AUTOSAR XML (schema 4-2-1)
package /RootP_ASWC_ParamServer
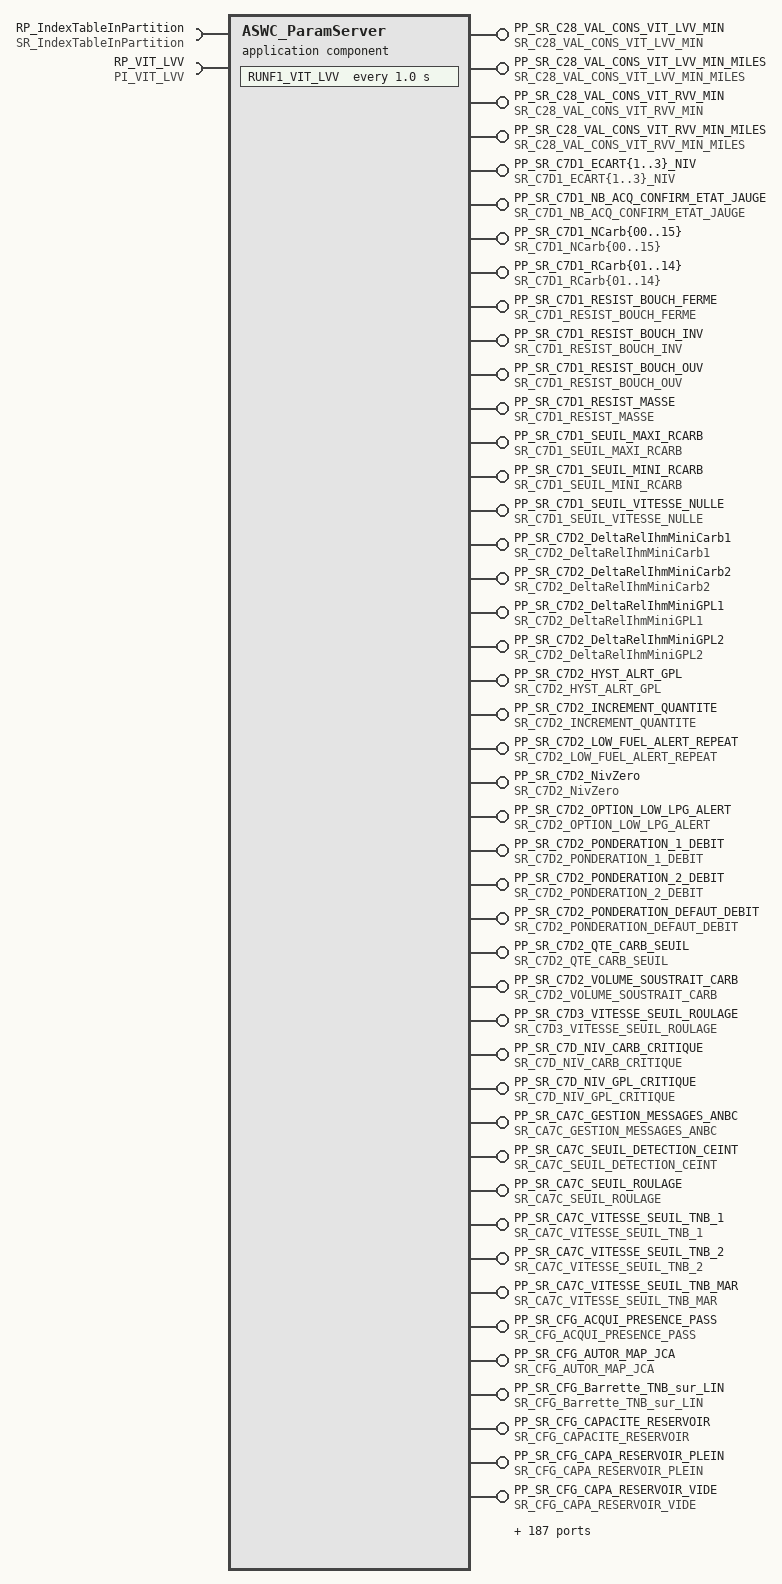
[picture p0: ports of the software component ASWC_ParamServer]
  application sw component type ASWC_ParamServer
    296 x provide port:
      PP_SR_C28_VAL_CONS_VIT_LVV_MIN: provided-interface=SR_C28_VAL_CONS_VIT_LVV_MIN
      PP_SR_C28_VAL_CONS_VIT_LVV_MIN_MILES: provided-interface=SR_C28_VAL_CONS_VIT_LVV_MIN_MILES
      PP_SR_C28_VAL_CONS_VIT_RVV_MIN: provided-interface=SR_C28_VAL_CONS_VIT_RVV_MIN
      PP_SR_C28_VAL_CONS_VIT_RVV_MIN_MILES: provided-interface=SR_C28_VAL_CONS_VIT_RVV_MIN_MILES
      PP_SR_C7D1_ECART{1..3}_NIV: nonqueued-sender-com-spec{data-element=C7D1_ECART{1..3}_NIV, uses-end-to-end-protection=0, init-value=0}, provided-interface=SR_C7D1_ECART{1..3}_NIV
      PP_SR_C7D1_NB_ACQ_CONFIRM_ETAT_JAUGE: nonqueued-sender-com-spec{data-element=C7D1_NB_ACQ_CONFIRM_ETAT_JAUGE, uses-end-to-end-protection=0, init-value=0}, provided-interface=SR_C7D1_NB_ACQ_CONFIRM_ETAT_JAUGE
      PP_SR_C7D1_NCarb{00..15}: nonqueued-sender-com-spec{data-element=C7D1_NCarb{00..15}, uses-end-to-end-protection=0, init-value=0}, provided-interface=SR_C7D1_NCarb{00..15}
      PP_SR_C7D1_RCarb{01..14}: nonqueued-sender-com-spec{data-element=C7D1_RCarb{01..14}, uses-end-to-end-protection=0, init-value=0}, provided-interface=SR_C7D1_RCarb{01..14}
      PP_SR_C7D1_RESIST_BOUCH_FERME: nonqueued-sender-com-spec{data-element=C7D1_RESIST_BOUCH_FERME, uses-end-to-end-protection=0, init-value=0}, provided-interface=SR_C7D1_RESIST_BOUCH_FERME
      PP_SR_C7D1_RESIST_BOUCH_INV: nonqueued-sender-com-spec{data-element=C7D1_RESIST_BOUCH_INV, uses-end-to-end-protection=0, init-value=0}, provided-interface=SR_C7D1_RESIST_BOUCH_INV
      PP_SR_C7D1_RESIST_BOUCH_OUV: nonqueued-sender-com-spec{data-element=C7D1_RESIST_BOUCH_OUV, uses-end-to-end-protection=0, init-value=0}, provided-interface=SR_C7D1_RESIST_BOUCH_OUV
      PP_SR_C7D1_RESIST_MASSE: nonqueued-sender-com-spec{data-element=C7D1_RESIST_MASSE, uses-end-to-end-protection=0, init-value=0}, provided-interface=SR_C7D1_RESIST_MASSE
      PP_SR_C7D1_SEUIL_MAXI_RCARB: nonqueued-sender-com-spec{data-element=C7D1_SEUIL_MAXI_RCARB, uses-end-to-end-protection=0, init-value=0}, provided-interface=SR_C7D1_SEUIL_MAXI_RCARB
      PP_SR_C7D1_SEUIL_MINI_RCARB: nonqueued-sender-com-spec{data-element=C7D1_SEUIL_MINI_RCARB, uses-end-to-end-protection=0, init-value=0}, provided-interface=SR_C7D1_SEUIL_MINI_RCARB
      PP_SR_C7D1_SEUIL_VITESSE_NULLE: nonqueued-sender-com-spec{data-element=C7D1_SEUIL_VITESSE_NULLE, uses-end-to-end-protection=0, init-value=0}, provided-interface=SR_C7D1_SEUIL_VITESSE_NULLE
      PP_SR_C7D2_DeltaRelIhmMiniCarb1: nonqueued-sender-com-spec{data-element=C7D2_DeltaRelIhmMiniCarb1, uses-end-to-end-protection=0, init-value=0}, provided-interface=SR_C7D2_DeltaRelIhmMiniCarb1
      PP_SR_C7D2_DeltaRelIhmMiniCarb2: nonqueued-sender-com-spec{data-element=C7D2_DeltaRelIhmMiniCarb2, uses-end-to-end-protection=0, init-value=0}, provided-interface=SR_C7D2_DeltaRelIhmMiniCarb2
      PP_SR_C7D2_DeltaRelIhmMiniGPL1: nonqueued-sender-com-spec{data-element=C7D2_DeltaRelIhmMiniGPL1, uses-end-to-end-protection=0, init-value=0}, provided-interface=SR_C7D2_DeltaRelIhmMiniGPL1
      PP_SR_C7D2_DeltaRelIhmMiniGPL2: nonqueued-sender-com-spec{data-element=C7D2_DeltaRelIhmMiniGPL2, uses-end-to-end-protection=0, init-value=0}, provided-interface=SR_C7D2_DeltaRelIhmMiniGPL2
      PP_SR_C7D2_HYST_ALRT_GPL: nonqueued-sender-com-spec{data-element=C7D2_HYST_ALRT_GPL, uses-end-to-end-protection=0, init-value=0}, provided-interface=SR_C7D2_HYST_ALRT_GPL
      PP_SR_C7D2_INCREMENT_QUANTITE: nonqueued-sender-com-spec{data-element=C7D2_INCREMENT_QUANTITE, uses-end-to-end-protection=0, init-value=0}, provided-interface=SR_C7D2_INCREMENT_QUANTITE
      PP_SR_C7D2_LOW_FUEL_ALERT_REPEAT: nonqueued-sender-com-spec{data-element=C7D2_LOW_FUEL_ALERT_REPEAT, uses-end-to-end-protection=0, init-value=0}, provided-interface=SR_C7D2_LOW_FUEL_ALERT_REPEAT
      PP_SR_C7D2_NivZero: nonqueued-sender-com-spec{data-element=C7D2_NivZero, uses-end-to-end-protection=0, init-value=0}, provided-interface=SR_C7D2_NivZero
      PP_SR_C7D2_OPTION_LOW_LPG_ALERT: nonqueued-sender-com-spec{data-element=C7D2_OPTION_LOW_LPG_ALERT, uses-end-to-end-protection=0, init-value=0}, provided-interface=SR_C7D2_OPTION_LOW_LPG_ALERT
      PP_SR_C7D2_PONDERATION_1_DEBIT: nonqueued-sender-com-spec{data-element=C7D2_PONDERATION_1_DEBIT, uses-end-to-end-protection=0, init-value=0}, provided-interface=SR_C7D2_PONDERATION_1_DEBIT
      PP_SR_C7D2_PONDERATION_2_DEBIT: nonqueued-sender-com-spec{data-element=C7D2_PONDERATION_2_DEBIT, uses-end-to-end-protection=0, init-value=0}, provided-interface=SR_C7D2_PONDERATION_2_DEBIT
      PP_SR_C7D2_PONDERATION_DEFAUT_DEBIT: nonqueued-sender-com-spec{data-element=C7D2_PONDERATION_DEFAUT_DEBIT, uses-end-to-end-protection=0, init-value=0}, provided-interface=SR_C7D2_PONDERATION_DEFAUT_DEBIT
      PP_SR_C7D2_QTE_CARB_SEUIL: nonqueued-sender-com-spec{data-element=C7D2_QTE_CARB_SEUIL, uses-end-to-end-protection=0, init-value=0}, provided-interface=SR_C7D2_QTE_CARB_SEUIL
      PP_SR_C7D2_VOLUME_SOUSTRAIT_CARB: nonqueued-sender-com-spec{data-element=C7D2_VOLUME_SOUSTRAIT_CARB, uses-end-to-end-protection=0, init-value=0}, provided-interface=SR_C7D2_VOLUME_SOUSTRAIT_CARB
      PP_SR_C7D3_VITESSE_SEUIL_ROULAGE: nonqueued-sender-com-spec{data-element=C7D3_VITESSE_SEUIL_ROULAGE, uses-end-to-end-protection=0, init-value=0}, provided-interface=SR_C7D3_VITESSE_SEUIL_ROULAGE
      PP_SR_C7D_NIV_CARB_CRITIQUE: nonqueued-sender-com-spec{data-element=C7D_NIV_CARB_CRITIQUE, uses-end-to-end-protection=0, init-value=0}, provided-interface=SR_C7D_NIV_CARB_CRITIQUE
      PP_SR_C7D_NIV_GPL_CRITIQUE: nonqueued-sender-com-spec{data-element=C7D_NIV_GPL_CRITIQUE, uses-end-to-end-protection=0, init-value=0}, provided-interface=SR_C7D_NIV_GPL_CRITIQUE
      PP_SR_CA7C_GESTION_MESSAGES_ANBC: nonqueued-sender-com-spec{data-element=CA7C_GESTION_MESSAGES_ANBC, uses-end-to-end-protection=0, init-value=0}, provided-interface=SR_CA7C_GESTION_MESSAGES_ANBC
      PP_SR_CA7C_SEUIL_DETECTION_CEINT: nonqueued-sender-com-spec{data-element=CA7C_SEUIL_DETECTION_CEINT, uses-end-to-end-protection=0, init-value=0}, provided-interface=SR_CA7C_SEUIL_DETECTION_CEINT
      PP_SR_CA7C_SEUIL_ROULAGE: nonqueued-sender-com-spec{data-element=CA7C_SEUIL_ROULAGE, uses-end-to-end-protection=0, init-value=0}, provided-interface=SR_CA7C_SEUIL_ROULAGE
      PP_SR_CA7C_VITESSE_SEUIL_TNB_1: nonqueued-sender-com-spec{data-element=CA7C_VITESSE_SEUIL_TNB_1, uses-end-to-end-protection=0, init-value=0}, provided-interface=SR_CA7C_VITESSE_SEUIL_TNB_1
      PP_SR_CA7C_VITESSE_SEUIL_TNB_2: nonqueued-sender-com-spec{data-element=CA7C_VITESSE_SEUIL_TNB_2, uses-end-to-end-protection=0, init-value=0}, provided-interface=SR_CA7C_VITESSE_SEUIL_TNB_2
      PP_SR_CA7C_VITESSE_SEUIL_TNB_MAR: nonqueued-sender-com-spec{data-element=CA7C_VITESSE_SEUIL_TNB_MAR, uses-end-to-end-protection=0, init-value=0}, provided-interface=SR_CA7C_VITESSE_SEUIL_TNB_MAR
      PP_SR_CFG_ACQUI_PRESENCE_PASS: nonqueued-sender-com-spec{data-element=CFG_ACQUI_PRESENCE_PASS, uses-end-to-end-protection=0, init-value=0}, provided-interface=SR_CFG_ACQUI_PRESENCE_PASS
      PP_SR_CFG_AUTOR_MAP_JCA: nonqueued-sender-com-spec{data-element=CFG_AUTOR_MAP_JCA, uses-end-to-end-protection=0, init-value=0}, provided-interface=SR_CFG_AUTOR_MAP_JCA
      PP_SR_CFG_Barrette_TNB_sur_LIN: nonqueued-sender-com-spec{data-element=CFG_Barrette_TNB_sur_LIN, uses-end-to-end-protection=0, init-value=0}, provided-interface=SR_CFG_Barrette_TNB_sur_LIN
      PP_SR_CFG_CAPACITE_RESERVOIR: nonqueued-sender-com-spec{data-element=CFG_CAPACITE_RESERVOIR, uses-end-to-end-protection=0, init-value=0}, provided-interface=SR_CFG_CAPACITE_RESERVOIR
      PP_SR_CFG_CAPA_RESERVOIR_PLEIN: nonqueued-sender-com-spec{data-element=CFG_CAPA_RESERVOIR_PLEIN, uses-end-to-end-protection=0, init-value=0}, provided-interface=SR_CFG_CAPA_RESERVOIR_PLEIN
      PP_SR_CFG_CAPA_RESERVOIR_VIDE: nonqueued-sender-com-spec{data-element=CFG_CAPA_RESERVOIR_VIDE, uses-end-to-end-protection=0, init-value=0}, provided-interface=SR_CFG_CAPA_RESERVOIR_VIDE
      PP_SR_CFG_DETECTION_PRES_NB_PAR2C: nonqueued-sender-com-spec{data-element=CFG_DETECTION_PRES_NB_PAR2C, uses-end-to-end-protection=0, init-value=0}, provided-interface=SR_CFG_DETECTION_PRES_NB_PAR2C
      PP_SR_CFG_DETECTION_PRES_NB_PAR2D: nonqueued-sender-com-spec{data-element=CFG_DETECTION_PRES_NB_PAR2D, uses-end-to-end-protection=0, init-value=0}, provided-interface=SR_CFG_DETECTION_PRES_NB_PAR2D
      PP_SR_CFG_DETECTION_PRES_NB_PAR2G: nonqueued-sender-com-spec{data-element=CFG_DETECTION_PRES_NB_PAR2G, uses-end-to-end-protection=0, init-value=0}, provided-interface=SR_CFG_DETECTION_PRES_NB_PAR2G
      PP_SR_CFG_DETECTION_PRES_NB_PAR3: nonqueued-sender-com-spec{data-element=CFG_DETECTION_PRES_NB_PAR3, uses-end-to-end-protection=0, init-value=0}, provided-interface=SR_CFG_DETECTION_PRES_NB_PAR3
      PP_SR_CFG_DETECT_APPORT_PAR_MVT: nonqueued-sender-com-spec{data-element=CFG_DETECT_APPORT_PAR_MVT, uses-end-to-end-protection=0, init-value=0}, provided-interface=SR_CFG_DETECT_APPORT_PAR_MVT
      PP_SR_CFG_INHIB_DIAG_TNB_COND: nonqueued-sender-com-spec{data-element=CFG_INHIB_DIAG_TNB_COND, uses-end-to-end-protection=0, init-value=0}, provided-interface=SR_CFG_INHIB_DIAG_TNB_COND
      PP_SR_CFG_INHIB_DIAG_TNB_PAR2C: nonqueued-sender-com-spec{data-element=CFG_INHIB_DIAG_TNB_PAR2C, uses-end-to-end-protection=0, init-value=0}, provided-interface=SR_CFG_INHIB_DIAG_TNB_PAR2C
      PP_SR_CFG_INHIB_DIAG_TNB_PAR2D: nonqueued-sender-com-spec{data-element=CFG_INHIB_DIAG_TNB_PAR2D, uses-end-to-end-protection=0, init-value=0}, provided-interface=SR_CFG_INHIB_DIAG_TNB_PAR2D
      PP_SR_CFG_INHIB_DIAG_TNB_PAR2G: nonqueued-sender-com-spec{data-element=CFG_INHIB_DIAG_TNB_PAR2G, uses-end-to-end-protection=0, init-value=0}, provided-interface=SR_CFG_INHIB_DIAG_TNB_PAR2G
      PP_SR_CFG_INHIB_DIAG_TNB_PAR3: nonqueued-sender-com-spec{data-element=CFG_INHIB_DIAG_TNB_PAR3, uses-end-to-end-protection=0, init-value=0}, provided-interface=SR_CFG_INHIB_DIAG_TNB_PAR3
      PP_SR_CFG_INHIB_DIAG_TNB_PAV: nonqueued-sender-com-spec{data-element=CFG_INHIB_DIAG_TNB_PAV, uses-end-to-end-protection=0, init-value=0}, provided-interface=SR_CFG_INHIB_DIAG_TNB_PAV
      PP_SR_CFG_INIT_AAS: nonqueued-sender-com-spec{data-element=CFG_INIT_AAS, uses-end-to-end-protection=0, init-value=0}, provided-interface=SR_CFG_INIT_AAS
      PP_SR_CFG_INIT_ACCUEIL_COND: nonqueued-sender-com-spec{data-element=CFG_INIT_ACCUEIL_COND, uses-end-to-end-protection=0, init-value=0}, provided-interface=SR_CFG_INIT_ACCUEIL_COND
      PP_SR_CFG_INIT_BAAACTIVATION: nonqueued-sender-com-spec{data-element=CFG_INIT_BAAACTIVATION, uses-end-to-end-protection=0, init-value=0}, provided-interface=SR_CFG_INIT_BAAACTIVATION
      PP_SR_CFG_INIT_BAAAUTOLOCKING: nonqueued-sender-com-spec{data-element=CFG_INIT_BAAAUTOLOCKING, uses-end-to-end-protection=0, init-value=0}, provided-interface=SR_CFG_INIT_BAAAUTOLOCKING
      PP_SR_CFG_INIT_BUTEE_{1..5}: nonqueued-sender-com-spec{data-element=CFG_INIT_BUTEE_{1..5}, uses-end-to-end-protection=0, init-value=0}, provided-interface=SR_CFG_INIT_BUTEE_{1..5}
      PP_SR_CFG_INIT_BUTEE_GENERALE: nonqueued-sender-com-spec{data-element=CFG_INIT_BUTEE_GENERALE, uses-end-to-end-protection=0, init-value=0}, provided-interface=SR_CFG_INIT_BUTEE_GENERALE
      PP_SR_CFG_INIT_CALAND: nonqueued-sender-com-spec{data-element=CFG_INIT_CALAND, uses-end-to-end-protection=0, init-value=0}, provided-interface=SR_CFG_INIT_CALAND
      PP_SR_CFG_INIT_CLIM_PRECOND_ASAP: nonqueued-sender-com-spec{data-element=CFG_INIT_CLIM_PRECOND_ASAP, uses-end-to-end-protection=0, init-value=0}, provided-interface=SR_CFG_INIT_CLIM_PRECOND_ASAP
      PP_SR_CFG_INIT_CLIM_PRECOND_DI_{1..4}: nonqueued-sender-com-spec{data-element=CFG_INIT_CLIM_PRECOND_DI_{1..4}, uses-end-to-end-protection=0, init-value=0}, provided-interface=SR_CFG_INIT_CLIM_PRECOND_DI_{1..4}
      PP_SR_CFG_INIT_CLIM_PRECOND_H_{1..4}: nonqueued-sender-com-spec{data-element=CFG_INIT_CLIM_PRECOND_H_{1..4}, uses-end-to-end-protection=0, init-value=0}, provided-interface=SR_CFG_INIT_CLIM_PRECOND_H_{1..4}
      PP_SR_CFG_INIT_CLIM_PRECOND_JE_{1..4}: nonqueued-sender-com-spec{data-element=CFG_INIT_CLIM_PRECOND_JE_{1..4}, uses-end-to-end-protection=0, init-value=0}, provided-interface=SR_CFG_INIT_CLIM_PRECOND_JE_{1..4}
      PP_SR_CFG_INIT_CLIM_PRECOND_LU_{1..4}: nonqueued-sender-com-spec{data-element=CFG_INIT_CLIM_PRECOND_LU_{1..4}, uses-end-to-end-protection=0, init-value=0}, provided-interface=SR_CFG_INIT_CLIM_PRECOND_LU_{1..4}
      PP_SR_CFG_INIT_CLIM_PRECOND_MA_{1..4}: nonqueued-sender-com-spec{data-element=CFG_INIT_CLIM_PRECOND_MA_{1..4}, uses-end-to-end-protection=0, init-value=0}, provided-interface=SR_CFG_INIT_CLIM_PRECOND_MA_{1..4}
      PP_SR_CFG_INIT_CLIM_PRECOND_ME_{1..4}: nonqueued-sender-com-spec{data-element=CFG_INIT_CLIM_PRECOND_ME_{1..4}, uses-end-to-end-protection=0, init-value=0}, provided-interface=SR_CFG_INIT_CLIM_PRECOND_ME_{1..4}
      PP_SR_CFG_INIT_CLIM_PRECOND_ON_{1..4}: nonqueued-sender-com-spec{data-element=CFG_INIT_CLIM_PRECOND_ON_{1..4}, uses-end-to-end-protection=0, init-value=0}, provided-interface=SR_CFG_INIT_CLIM_PRECOND_ON_{1..4}
      PP_SR_CFG_INIT_CLIM_PRECOND_SA_{1..4}: nonqueued-sender-com-spec{data-element=CFG_INIT_CLIM_PRECOND_SA_{1..4}, uses-end-to-end-protection=0, init-value=0}, provided-interface=SR_CFG_INIT_CLIM_PRECOND_SA_{1..4}
      PP_SR_CFG_INIT_CLIM_PRECOND_VE_{1..4}: nonqueued-sender-com-spec{data-element=CFG_INIT_CLIM_PRECOND_VE_{1..4}, uses-end-to-end-protection=0, init-value=0}, provided-interface=SR_CFG_INIT_CLIM_PRECOND_VE_{1..4}
      PP_SR_CFG_INIT_CMDM_DAE: nonqueued-sender-com-spec{data-element=CFG_INIT_CMDM_DAE, uses-end-to-end-protection=0, init-value=0}, provided-interface=SR_CFG_INIT_CMDM_DAE
      PP_SR_CFG_INIT_CMDM_DAE_4WD: nonqueued-sender-com-spec{data-element=CFG_INIT_CMDM_DAE_4WD, uses-end-to-end-protection=0, init-value=0}, provided-interface=SR_CFG_INIT_CMDM_DAE_4WD
      PP_SR_CFG_INIT_DAAACTIVATION: nonqueued-sender-com-spec{data-element=CFG_INIT_DAAACTIVATION, uses-end-to-end-protection=0, init-value=0}, provided-interface=SR_CFG_INIT_DAAACTIVATION
      PP_SR_CFG_INIT_DSG: nonqueued-sender-com-spec{data-element=CFG_INIT_DSG, uses-end-to-end-protection=0, init-value=0}, provided-interface=SR_CFG_INIT_DSG
      PP_SR_CFG_INIT_ECLI_PPC_ANIM: nonqueued-sender-com-spec{data-element=CFG_INIT_ECLI_PPC_ANIM, uses-end-to-end-protection=0, init-value=0}, provided-interface=SR_CFG_INIT_ECLI_PPC_ANIM
      PP_SR_CFG_INIT_ECLI_PPC_BLOC1: nonqueued-sender-com-spec{data-element=CFG_INIT_ECLI_PPC_BLOC1, uses-end-to-end-protection=0, init-value=0}, provided-interface=SR_CFG_INIT_ECLI_PPC_BLOC1
      PP_SR_CFG_INIT_ECLI_PPC_COL1: nonqueued-sender-com-spec{data-element=CFG_INIT_ECLI_PPC_COL1, uses-end-to-end-protection=0, init-value=0}, provided-interface=SR_CFG_INIT_ECLI_PPC_COL1
      PP_SR_CFG_INIT_ECLX_AFS: nonqueued-sender-com-spec{data-element=CFG_INIT_ECLX_AFS, uses-end-to-end-protection=0, init-value=0}, provided-interface=SR_CFG_INIT_ECLX_AFS
      PP_SR_CFG_INIT_ECLX_ARS: nonqueued-sender-com-spec{data-element=CFG_INIT_ECLX_ARS, uses-end-to-end-protection=0, init-value=0}, provided-interface=SR_CFG_INIT_ECLX_ARS
      PP_SR_CFG_INIT_ECLX_ECL_CAFR: nonqueued-sender-com-spec{data-element=CFG_INIT_ECLX_ECL_CAFR, uses-end-to-end-protection=0, init-value=0}, provided-interface=SR_CFG_INIT_ECLX_ECL_CAFR
      PP_SR_CFG_INIT_ECL_ACCOMP: nonqueued-sender-com-spec{data-element=CFG_INIT_ECL_ACCOMP, uses-end-to-end-protection=0, init-value=0}, provided-interface=SR_CFG_INIT_ECL_ACCOMP
      PP_SR_CFG_INIT_ECL_ADAPT: nonqueued-sender-com-spec{data-element=CFG_INIT_ECL_ADAPT, uses-end-to-end-protection=0, init-value=0}, provided-interface=SR_CFG_INIT_ECL_ADAPT
      PP_SR_CFG_INIT_ECL_AMBI: nonqueued-sender-com-spec{data-element=CFG_INIT_ECL_AMBI, uses-end-to-end-protection=0, init-value=0}, provided-interface=SR_CFG_INIT_ECL_AMBI
      PP_SR_CFG_INIT_ECL_AMBI_NIV: nonqueued-sender-com-spec{data-element=CFG_INIT_ECL_AMBI_NIV, uses-end-to-end-protection=0, init-value=0}, provided-interface=SR_CFG_INIT_ECL_AMBI_NIV
      PP_SR_CFG_INIT_ECL_AUTO: nonqueued-sender-com-spec{data-element=CFG_INIT_ECL_AUTO, uses-end-to-end-protection=0, init-value=0}, provided-interface=SR_CFG_INIT_ECL_AUTO
      PP_SR_CFG_INIT_ECL_AUTOROUTE: nonqueued-sender-com-spec{data-element=CFG_INIT_ECL_AUTOROUTE, uses-end-to-end-protection=0, init-value=0}, provided-interface=SR_CFG_INIT_ECL_AUTOROUTE
      PP_SR_CFG_INIT_ECL_DECONDA: nonqueued-sender-com-spec{data-element=CFG_INIT_ECL_DECONDA, uses-end-to-end-protection=0, init-value=0}, provided-interface=SR_CFG_INIT_ECL_DECONDA
      PP_SR_CFG_INIT_ECL_FEUX_DIURNES: nonqueued-sender-com-spec{data-element=CFG_INIT_ECL_FEUX_DIURNES, uses-end-to-end-protection=0, init-value=0}, provided-interface=SR_CFG_INIT_ECL_FEUX_DIURNES
      PP_SR_CFG_INIT_ESSUIE_VIT_MAR: nonqueued-sender-com-spec{data-element=CFG_INIT_ESSUIE_VIT_MAR, uses-end-to-end-protection=0, init-value=0}, provided-interface=SR_CFG_INIT_ESSUIE_VIT_MAR
      PP_SR_CFG_INIT_FARC: nonqueued-sender-com-spec{data-element=CFG_INIT_FARC, uses-end-to-end-protection=0, init-value=0}, provided-interface=SR_CFG_INIT_FARC
      PP_SR_CFG_INIT_FSE_AUTO: nonqueued-sender-com-spec{data-element=CFG_INIT_FSE_AUTO, uses-end-to-end-protection=0, init-value=0}, provided-interface=SR_CFG_INIT_FSE_AUTO
      PP_SR_CFG_INIT_GAV_AMLA: nonqueued-sender-com-spec{data-element=CFG_INIT_GAV_AMLA, uses-end-to-end-protection=0, init-value=0}, provided-interface=SR_CFG_INIT_GAV_AMLA
      PP_SR_CFG_INIT_HARMONIE_SON: nonqueued-sender-com-spec{data-element=CFG_INIT_HARMONIE_SON, uses-end-to-end-protection=0, init-value=0}, provided-interface=SR_CFG_INIT_HARMONIE_SON
      PP_SR_CFG_INIT_ILV: nonqueued-sender-com-spec{data-element=CFG_INIT_ILV, uses-end-to-end-protection=0, init-value=0}, provided-interface=SR_CFG_INIT_ILV
      PP_SR_CFG_INIT_ILV_ETSR: nonqueued-sender-com-spec{data-element=CFG_INIT_ILV_ETSR, uses-end-to-end-protection=0, init-value=0}, provided-interface=SR_CFG_INIT_ILV_ETSR
      PP_SR_CFG_INIT_IMA: nonqueued-sender-com-spec{data-element=CFG_INIT_IMA, uses-end-to-end-protection=0, init-value=0}, provided-interface=SR_CFG_INIT_IMA
      PP_SR_CFG_INIT_INV_ADSD: nonqueued-sender-com-spec{data-element=CFG_INIT_INV_ADSD, uses-end-to-end-protection=0, init-value=0}, provided-interface=SR_CFG_INIT_INV_ADSD
      PP_SR_CFG_INIT_LANGUE_VHL: nonqueued-sender-com-spec{data-element=CFG_INIT_LANGUE_VHL, uses-end-to-end-protection=0, init-value=0}, provided-interface=SR_CFG_INIT_LANGUE_VHL
      PP_SR_CFG_INIT_MENU_HC_END: nonqueued-sender-com-spec{data-element=CFG_INIT_MENU_HC_END, uses-end-to-end-protection=0, init-value=0}, provided-interface=SR_CFG_INIT_MENU_HC_END
      PP_SR_CFG_INIT_MENU_HC_START: nonqueued-sender-com-spec{data-element=CFG_INIT_MENU_HC_START, uses-end-to-end-protection=0, init-value=0}, provided-interface=SR_CFG_INIT_MENU_HC_START
      PP_SR_CFG_INIT_MENU_PRG_PEM_DI: nonqueued-sender-com-spec{data-element=CFG_INIT_MENU_PRG_PEM_DI, uses-end-to-end-protection=0, init-value=0}, provided-interface=SR_CFG_INIT_MENU_PRG_PEM_DI
      PP_SR_CFG_INIT_MENU_PRG_PEM_JE: nonqueued-sender-com-spec{data-element=CFG_INIT_MENU_PRG_PEM_JE, uses-end-to-end-protection=0, init-value=0}, provided-interface=SR_CFG_INIT_MENU_PRG_PEM_JE
      PP_SR_CFG_INIT_MENU_PRG_PEM_LU: nonqueued-sender-com-spec{data-element=CFG_INIT_MENU_PRG_PEM_LU, uses-end-to-end-protection=0, init-value=0}, provided-interface=SR_CFG_INIT_MENU_PRG_PEM_LU
      PP_SR_CFG_INIT_MENU_PRG_PEM_MA: nonqueued-sender-com-spec{data-element=CFG_INIT_MENU_PRG_PEM_MA, uses-end-to-end-protection=0, init-value=0}, provided-interface=SR_CFG_INIT_MENU_PRG_PEM_MA
      PP_SR_CFG_INIT_MENU_PRG_PEM_ME: nonqueued-sender-com-spec{data-element=CFG_INIT_MENU_PRG_PEM_ME, uses-end-to-end-protection=0, init-value=0}, provided-interface=SR_CFG_INIT_MENU_PRG_PEM_ME
      PP_SR_CFG_INIT_MENU_PRG_PEM_SA: nonqueued-sender-com-spec{data-element=CFG_INIT_MENU_PRG_PEM_SA, uses-end-to-end-protection=0, init-value=0}, provided-interface=SR_CFG_INIT_MENU_PRG_PEM_SA
      PP_SR_CFG_INIT_MENU_PRG_PEM_VE: nonqueued-sender-com-spec{data-element=CFG_INIT_MENU_PRG_PEM_VE, uses-end-to-end-protection=0, init-value=0}, provided-interface=SR_CFG_INIT_MENU_PRG_PEM_VE
      PP_SR_CFG_INIT_MENU_SEL_HC: nonqueued-sender-com-spec{data-element=CFG_INIT_MENU_SEL_HC, uses-end-to-end-protection=0, init-value=0}, provided-interface=SR_CFG_INIT_MENU_SEL_HC
      PP_SR_CFG_INIT_MENU_SEL_PRG_PEM_DI: nonqueued-sender-com-spec{data-element=CFG_INIT_MENU_SEL_PRG_PEM_DI, uses-end-to-end-protection=0, init-value=0}, provided-interface=SR_CFG_INIT_MENU_SEL_PRG_PEM_DI
      PP_SR_CFG_INIT_MENU_SEL_PRG_PEM_JE: nonqueued-sender-com-spec{data-element=CFG_INIT_MENU_SEL_PRG_PEM_JE, uses-end-to-end-protection=0, init-value=0}, provided-interface=SR_CFG_INIT_MENU_SEL_PRG_PEM_JE
      PP_SR_CFG_INIT_MENU_SEL_PRG_PEM_LU: nonqueued-sender-com-spec{data-element=CFG_INIT_MENU_SEL_PRG_PEM_LU, uses-end-to-end-protection=0, init-value=0}, provided-interface=SR_CFG_INIT_MENU_SEL_PRG_PEM_LU
      PP_SR_CFG_INIT_MENU_SEL_PRG_PEM_MA: nonqueued-sender-com-spec{data-element=CFG_INIT_MENU_SEL_PRG_PEM_MA, uses-end-to-end-protection=0, init-value=0}, provided-interface=SR_CFG_INIT_MENU_SEL_PRG_PEM_MA
      PP_SR_CFG_INIT_MENU_SEL_PRG_PEM_ME: nonqueued-sender-com-spec{data-element=CFG_INIT_MENU_SEL_PRG_PEM_ME, uses-end-to-end-protection=0, init-value=0}, provided-interface=SR_CFG_INIT_MENU_SEL_PRG_PEM_ME
      PP_SR_CFG_INIT_MENU_SEL_PRG_PEM_SA: nonqueued-sender-com-spec{data-element=CFG_INIT_MENU_SEL_PRG_PEM_SA, uses-end-to-end-protection=0, init-value=0}, provided-interface=SR_CFG_INIT_MENU_SEL_PRG_PEM_SA
      PP_SR_CFG_INIT_MENU_SEL_PRG_PEM_VE: nonqueued-sender-com-spec{data-element=CFG_INIT_MENU_SEL_PRG_PEM_VE, uses-end-to-end-protection=0, init-value=0}, provided-interface=SR_CFG_INIT_MENU_SEL_PRG_PEM_VE
      PP_SR_CFG_INIT_MOTOR_VOLET: nonqueued-sender-com-spec{data-element=CFG_INIT_MOTOR_VOLET, uses-end-to-end-protection=0, init-value=0}, provided-interface=SR_CFG_INIT_MOTOR_VOLET
      PP_SR_CFG_INIT_PRESENCE_ARC: nonqueued-sender-com-spec{data-element=CFG_INIT_PRESENCE_ARC, uses-end-to-end-protection=0, init-value=0}, provided-interface=SR_CFG_INIT_PRESENCE_ARC
      PP_SR_CFG_INIT_PRV_MODE: nonqueued-sender-com-spec{data-element=CFG_INIT_PRV_MODE, uses-end-to-end-protection=0, init-value=0}, provided-interface=SR_CFG_INIT_PRV_MODE
      PP_SR_CFG_INIT_RESERVE_ZEV: nonqueued-sender-com-spec{data-element=CFG_INIT_RESERVE_ZEV, uses-end-to-end-protection=0, init-value=0}, provided-interface=SR_CFG_INIT_RESERVE_ZEV
      PP_SR_CFG_INIT_RTAB: nonqueued-sender-com-spec{data-element=CFG_INIT_RTAB, uses-end-to-end-protection=0, init-value=0}, provided-interface=SR_CFG_INIT_RTAB
      PP_SR_CFG_INIT_RTAB_ENERGY_REC: nonqueued-sender-com-spec{data-element=CFG_INIT_RTAB_ENERGY_REC, uses-end-to-end-protection=0, init-value=0}, provided-interface=SR_CFG_INIT_RTAB_ENERGY_REC
      PP_SR_CFG_INIT_RTAB_RECHARGE: nonqueued-sender-com-spec{data-element=CFG_INIT_RTAB_RECHARGE, uses-end-to-end-protection=0, init-value=0}, provided-interface=SR_CFG_INIT_RTAB_RECHARGE
      PP_SR_CFG_INIT_RTAB_RECHARGE_H_DEB: nonqueued-sender-com-spec{data-element=CFG_INIT_RTAB_RECHARGE_H_DEB, uses-end-to-end-protection=0, init-value=0}, provided-interface=SR_CFG_INIT_RTAB_RECHARGE_H_DEB
      PP_SR_CFG_INIT_RTAB_TYPE_REC: nonqueued-sender-com-spec{data-element=CFG_INIT_RTAB_TYPE_REC, uses-end-to-end-protection=0, init-value=0}, provided-interface=SR_CFG_INIT_RTAB_TYPE_REC
      PP_SR_CFG_INIT_SAM: nonqueued-sender-com-spec{data-element=CFG_INIT_SAM, uses-end-to-end-protection=0, init-value=0}, provided-interface=SR_CFG_INIT_SAM
      PP_SR_CFG_INIT_SELECTIVITE_CAB_ZC: nonqueued-sender-com-spec{data-element=CFG_INIT_SELECTIVITE_CAB_ZC, uses-end-to-end-protection=0, init-value=0}, provided-interface=SR_CFG_INIT_SELECTIVITE_CAB_ZC
      PP_SR_CFG_INIT_SELECTIVITE_COND: nonqueued-sender-com-spec{data-element=CFG_INIT_SELECTIVITE_COND, uses-end-to-end-protection=0, init-value=0}, provided-interface=SR_CFG_INIT_SELECTIVITE_COND
      PP_SR_CFG_INIT_SELECTIVITE_OUV_AR: nonqueued-sender-com-spec{data-element=CFG_INIT_SELECTIVITE_OUV_AR, uses-end-to-end-protection=0, init-value=0}, provided-interface=SR_CFG_INIT_SELECTIVITE_OUV_AR
      PP_SR_CFG_INIT_SEL_RESERVE_ZEV: nonqueued-sender-com-spec{data-element=CFG_INIT_SEL_RESERVE_ZEV, uses-end-to-end-protection=0, init-value=0}, provided-interface=SR_CFG_INIT_SEL_RESERVE_ZEV
      PP_SR_CFG_INIT_SENS_ARC_NIV: nonqueued-sender-com-spec{data-element=CFG_INIT_SENS_ARC_NIV, uses-end-to-end-protection=0, init-value=0}, provided-interface=SR_CFG_INIT_SENS_ARC_NIV
      PP_SR_CFG_INIT_TCFG: nonqueued-sender-com-spec{data-element=CFG_INIT_TCFG, uses-end-to-end-protection=0, init-value=0}, provided-interface=SR_CFG_INIT_TCFG
      PP_SR_CFG_INIT_TEMPO_ACCOMP: nonqueued-sender-com-spec{data-element=CFG_INIT_TEMPO_ACCOMP, uses-end-to-end-protection=0, init-value=0}, provided-interface=SR_CFG_INIT_TEMPO_ACCOMP
      PP_SR_CFG_INIT_TEMPO_DECONDA: nonqueued-sender-com-spec{data-element=CFG_INIT_TEMPO_DECONDA, uses-end-to-end-protection=0, init-value=0}, provided-interface=SR_CFG_INIT_TEMPO_DECONDA
      PP_SR_CFG_INIT_UNITE_CONSO: nonqueued-sender-com-spec{data-element=CFG_INIT_UNITE_CONSO, uses-end-to-end-protection=0, init-value=0}, provided-interface=SR_CFG_INIT_UNITE_CONSO
      PP_SR_CFG_INIT_UNITE_DISTANCE: nonqueued-sender-com-spec{data-element=CFG_INIT_UNITE_DISTANCE, uses-end-to-end-protection=0, init-value=0}, provided-interface=SR_CFG_INIT_UNITE_DISTANCE
      PP_SR_CFG_INIT_UNITE_TEMP: nonqueued-sender-com-spec{data-element=CFG_INIT_UNITE_TEMP, uses-end-to-end-protection=0, init-value=0}, provided-interface=SR_CFG_INIT_UNITE_TEMP
      PP_SR_CFG_INIT_UNITE_VOLUME: nonqueued-sender-com-spec{data-element=CFG_INIT_UNITE_VOLUME, uses-end-to-end-protection=0, init-value=0}, provided-interface=SR_CFG_INIT_UNITE_VOLUME
      PP_SR_CFG_INIT_VAM_ECS_MODE: nonqueued-sender-com-spec{data-element=CFG_INIT_VAM_ECS_MODE, uses-end-to-end-protection=0, init-value=0}, provided-interface=SR_CFG_INIT_VAM_ECS_MODE
      PP_SR_CFG_INIT_VITESSE_{1..5}: nonqueued-sender-com-spec{data-element=CFG_INIT_VITESSE_{1..5}, uses-end-to-end-protection=0, init-value=0}, provided-interface=SR_CFG_INIT_VITESSE_{1..5}
      PP_SR_CFG_INIT_VIT_LVV_1: nonqueued-sender-com-spec{data-element=CFG_INIT_VIT_LVV_1, uses-end-to-end-protection=0, init-value=0}, provided-interface=SR_CFG_INIT_VIT_LVV_1
      PP_SR_CFG_INIT_VIT_LVV_1_Miles: nonqueued-sender-com-spec{data-element=CFG_INIT_VIT_LVV_1_Miles, uses-end-to-end-protection=0, init-value=0}, provided-interface=SR_CFG_INIT_VIT_LVV_1_Miles
      PP_SR_CFG_INIT_VIT_LVV_2: nonqueued-sender-com-spec{data-element=CFG_INIT_VIT_LVV_2, uses-end-to-end-protection=0, init-value=0}, provided-interface=SR_CFG_INIT_VIT_LVV_2
      PP_SR_CFG_INIT_VIT_LVV_2_Miles: nonqueued-sender-com-spec{data-element=CFG_INIT_VIT_LVV_2_Miles, uses-end-to-end-protection=0, init-value=0}, provided-interface=SR_CFG_INIT_VIT_LVV_2_Miles
      PP_SR_CFG_INIT_VIT_LVV_3: nonqueued-sender-com-spec{data-element=CFG_INIT_VIT_LVV_3, uses-end-to-end-protection=0, init-value=0}, provided-interface=SR_CFG_INIT_VIT_LVV_3
      PP_SR_CFG_INIT_VIT_LVV_3_Miles: nonqueued-sender-com-spec{data-element=CFG_INIT_VIT_LVV_3_Miles, uses-end-to-end-protection=0, init-value=0}, provided-interface=SR_CFG_INIT_VIT_LVV_3_Miles
      PP_SR_CFG_INIT_VIT_LVV_4: nonqueued-sender-com-spec{data-element=CFG_INIT_VIT_LVV_4, uses-end-to-end-protection=0, init-value=0}, provided-interface=SR_CFG_INIT_VIT_LVV_4
      PP_SR_CFG_INIT_VIT_LVV_4_Miles: nonqueued-sender-com-spec{data-element=CFG_INIT_VIT_LVV_4_Miles, uses-end-to-end-protection=0, init-value=0}, provided-interface=SR_CFG_INIT_VIT_LVV_4_Miles
      PP_SR_CFG_INIT_VIT_LVV_5: nonqueued-sender-com-spec{data-element=CFG_INIT_VIT_LVV_5, uses-end-to-end-protection=0, init-value=0}, provided-interface=SR_CFG_INIT_VIT_LVV_5
      PP_SR_CFG_INIT_VIT_LVV_5_Miles: nonqueued-sender-com-spec{data-element=CFG_INIT_VIT_LVV_5_Miles, uses-end-to-end-protection=0, init-value=0}, provided-interface=SR_CFG_INIT_VIT_LVV_5_Miles
      PP_SR_CFG_INIT_VIT_LVV_6: nonqueued-sender-com-spec{data-element=CFG_INIT_VIT_LVV_6, uses-end-to-end-protection=0, init-value=0}, provided-interface=SR_CFG_INIT_VIT_LVV_6
      PP_SR_CFG_INIT_VIT_LVV_6_Miles: nonqueued-sender-com-spec{data-element=CFG_INIT_VIT_LVV_6_Miles, uses-end-to-end-protection=0, init-value=0}, provided-interface=SR_CFG_INIT_VIT_LVV_6_Miles
      PP_SR_CFG_INIT_VIT_RVV_1: nonqueued-sender-com-spec{data-element=CFG_INIT_VIT_RVV_1, uses-end-to-end-protection=0, init-value=0}, provided-interface=SR_CFG_INIT_VIT_RVV_1
      PP_SR_CFG_INIT_VIT_RVV_1_Miles: nonqueued-sender-com-spec{data-element=CFG_INIT_VIT_RVV_1_Miles, uses-end-to-end-protection=0, init-value=0}, provided-interface=SR_CFG_INIT_VIT_RVV_1_Miles
      PP_SR_CFG_INIT_VIT_RVV_2: nonqueued-sender-com-spec{data-element=CFG_INIT_VIT_RVV_2, uses-end-to-end-protection=0, init-value=0}, provided-interface=SR_CFG_INIT_VIT_RVV_2
      PP_SR_CFG_INIT_VIT_RVV_2_Miles: nonqueued-sender-com-spec{data-element=CFG_INIT_VIT_RVV_2_Miles, uses-end-to-end-protection=0, init-value=0}, provided-interface=SR_CFG_INIT_VIT_RVV_2_Miles
      PP_SR_CFG_INIT_VIT_RVV_3: nonqueued-sender-com-spec{data-element=CFG_INIT_VIT_RVV_3, uses-end-to-end-protection=0, init-value=0}, provided-interface=SR_CFG_INIT_VIT_RVV_3
      PP_SR_CFG_INIT_VIT_RVV_3_Miles: nonqueued-sender-com-spec{data-element=CFG_INIT_VIT_RVV_3_Miles, uses-end-to-end-protection=0, init-value=0}, provided-interface=SR_CFG_INIT_VIT_RVV_3_Miles
      PP_SR_CFG_INIT_VIT_RVV_4: nonqueued-sender-com-spec{data-element=CFG_INIT_VIT_RVV_4, uses-end-to-end-protection=0, init-value=0}, provided-interface=SR_CFG_INIT_VIT_RVV_4
      PP_SR_CFG_INIT_VIT_RVV_4_Miles: nonqueued-sender-com-spec{data-element=CFG_INIT_VIT_RVV_4_Miles, uses-end-to-end-protection=0, init-value=0}, provided-interface=SR_CFG_INIT_VIT_RVV_4_Miles
      PP_SR_CFG_INIT_VIT_RVV_5: nonqueued-sender-com-spec{data-element=CFG_INIT_VIT_RVV_5, uses-end-to-end-protection=0, init-value=0}, provided-interface=SR_CFG_INIT_VIT_RVV_5
      PP_SR_CFG_INIT_VIT_RVV_5_Miles: nonqueued-sender-com-spec{data-element=CFG_INIT_VIT_RVV_5_Miles, uses-end-to-end-protection=0, init-value=0}, provided-interface=SR_CFG_INIT_VIT_RVV_5_Miles
      PP_SR_CFG_INIT_VIT_RVV_6: nonqueued-sender-com-spec{data-element=CFG_INIT_VIT_RVV_6, uses-end-to-end-protection=0, init-value=0}, provided-interface=SR_CFG_INIT_VIT_RVV_6
      PP_SR_CFG_INIT_VIT_RVV_6_Miles: nonqueued-sender-com-spec{data-element=CFG_INIT_VIT_RVV_6_Miles, uses-end-to-end-protection=0, init-value=0}, provided-interface=SR_CFG_INIT_VIT_RVV_6_Miles
      PP_SR_CFG_INIT_VTOR_IRV: nonqueued-sender-com-spec{data-element=CFG_INIT_VTOR_IRV, uses-end-to-end-protection=0, init-value=0}, provided-interface=SR_CFG_INIT_VTOR_IRV
      PP_SR_CFG_MECATRONIC_HEADLAMP: nonqueued-sender-com-spec{data-element=CFG_MECATRONIC_HEADLAMP, uses-end-to-end-protection=0, init-value=0}, provided-interface=SR_CFG_MECATRONIC_HEADLAMP
      PP_SR_CFG_NAPPE_DETECTION_PASS: nonqueued-sender-com-spec{data-element=CFG_NAPPE_DETECTION_PASS, uses-end-to-end-protection=0, init-value=0}, provided-interface=SR_CFG_NAPPE_DETECTION_PASS
      PP_SR_CFG_NBR_CNB: nonqueued-sender-com-spec{data-element=CFG_NBR_CNB, uses-end-to-end-protection=0, init-value=0}, provided-interface=SR_CFG_NBR_CNB
      PP_SR_CFG_NB_MAX_TABLE_JC: nonqueued-sender-com-spec{data-element=CFG_NB_MAX_TABLE_JC, uses-end-to-end-protection=0, init-value=0}, provided-interface=SR_CFG_NB_MAX_TABLE_JC
      PP_SR_CFG_NIV_ALERTE_MINI_CARB: nonqueued-sender-com-spec{data-element=CFG_NIV_ALERTE_MINI_CARB, uses-end-to-end-protection=0, init-value=0}, provided-interface=SR_CFG_NIV_ALERTE_MINI_CARB
      PP_SR_CFG_NIV_ALERTE_MINI_GPL: nonqueued-sender-com-spec{data-element=CFG_NIV_ALERTE_MINI_GPL, uses-end-to-end-protection=0, init-value=0}, provided-interface=SR_CFG_NIV_ALERTE_MINI_GPL
      PP_SR_CFG_NUM_TABLE_CARB: nonqueued-sender-com-spec{data-element=CFG_NUM_TABLE_CARB, uses-end-to-end-protection=0, init-value=0}, provided-interface=SR_CFG_NUM_TABLE_CARB
      PP_SR_CFG_OPTION_MENU_FSE: nonqueued-sender-com-spec{data-element=CFG_OPTION_MENU_FSE, uses-end-to-end-protection=0, init-value=0}, provided-interface=SR_CFG_OPTION_MENU_FSE
      PP_SR_CFG_OPTION_PAVC_PRES_DETECTION: nonqueued-sender-com-spec{data-element=CFG_OPTION_PAVC_PRES_DETECTION, uses-end-to-end-protection=0, init-value=0}, provided-interface=SR_CFG_OPTION_PAVC_PRES_DETECTION
      PP_SR_CFG_OPTION_TAXI: nonqueued-sender-com-spec{data-element=CFG_OPTION_TAXI, uses-end-to-end-protection=0, init-value=0}, provided-interface=SR_CFG_OPTION_TAXI
      PP_SR_CFG_PRESENCE_AFS: nonqueued-sender-com-spec{data-element=CFG_PRESENCE_AFS, uses-end-to-end-protection=0, init-value=0}, provided-interface=SR_CFG_PRESENCE_AFS
      PP_SR_CFG_PRESENCE_ARC: nonqueued-sender-com-spec{data-element=CFG_PRESENCE_ARC, uses-end-to-end-protection=0, init-value=0}, provided-interface=SR_CFG_PRESENCE_ARC
      PP_SR_CFG_PRESENCE_CLE_INHIB_RBG_PASS: nonqueued-sender-com-spec{data-element=CFG_PRESENCE_CLE_INHIB_RBG_PASS, uses-end-to-end-protection=0, init-value=0}, provided-interface=SR_CFG_PRESENCE_CLE_INHIB_RBG_PASS
      PP_SR_CFG_PRESENCE_ECR: nonqueued-sender-com-spec{data-element=CFG_PRESENCE_ECR, uses-end-to-end-protection=0, init-value=0}, provided-interface=SR_CFG_PRESENCE_ECR
      PP_SR_CFG_PRESENCE_FARC: nonqueued-sender-com-spec{data-element=CFG_PRESENCE_FARC, uses-end-to-end-protection=0, init-value=0}, provided-interface=SR_CFG_PRESENCE_FARC
      PP_SR_CFG_PRESENCE_GAZ: nonqueued-sender-com-spec{data-element=CFG_PRESENCE_GAZ, uses-end-to-end-protection=0, init-value=0}, provided-interface=SR_CFG_PRESENCE_GAZ
      PP_SR_CFG_PRESENCE_ISOFIX_AV: nonqueued-sender-com-spec{data-element=CFG_PRESENCE_ISOFIX_AV, uses-end-to-end-protection=0, init-value=0}, provided-interface=SR_CFG_PRESENCE_ISOFIX_AV
      PP_SR_CFG_PRESENCE_MENU_PERSO: nonqueued-sender-com-spec{data-element=CFG_PRESENCE_MENU_PERSO, uses-end-to-end-protection=0, init-value=0}, provided-interface=SR_CFG_PRESENCE_MENU_PERSO
      PP_SR_CFG_PRESENCE_MSG_ANBC_COND: nonqueued-sender-com-spec{data-element=CFG_PRESENCE_MSG_ANBC_COND, uses-end-to-end-protection=0, init-value=0}, provided-interface=SR_CFG_PRESENCE_MSG_ANBC_COND
      PP_SR_CFG_PRESENCE_TO: nonqueued-sender-com-spec{data-element=CFG_PRESENCE_TO, uses-end-to-end-protection=0, init-value=0}, provided-interface=SR_CFG_PRESENCE_TO
      PP_SR_CFG_PRESENCE_TOUCHE_CONFIG: nonqueued-sender-com-spec{data-element=CFG_PRESENCE_TOUCHE_CONFIG, uses-end-to-end-protection=0, init-value=0}, provided-interface=SR_CFG_PRESENCE_TOUCHE_CONFIG
      PP_SR_CFG_STEERING_WHEEL_POSITION: nonqueued-sender-com-spec{data-element=CFG_STEERING_WHEEL_POSITION, uses-end-to-end-protection=0, init-value=0}, provided-interface=SR_CFG_STEERING_WHEEL_POSITION
      PP_SR_CFG_TYPE_AAS: nonqueued-sender-com-spec{data-element=CFG_TYPE_AAS, uses-end-to-end-protection=0, init-value=0}, provided-interface=SR_CFG_TYPE_AAS
      PP_SR_CFG_TYPE_ACTIVATION_AFS: nonqueued-sender-com-spec{data-element=CFG_TYPE_ACTIVATION_AFS, uses-end-to-end-protection=0, init-value=0}, provided-interface=SR_CFG_TYPE_ACTIVATION_AFS
      PP_SR_CFG_TYPE_ANBC: nonqueued-sender-com-spec{data-element=CFG_TYPE_ANBC, uses-end-to-end-protection=0, init-value=0}, provided-interface=SR_CFG_TYPE_ANBC
      PP_SR_CFG_TYPE_CAPTEUR_BOUCHON_CARB: nonqueued-sender-com-spec{data-element=CFG_TYPE_CAPTEUR_BOUCHON_CARB, uses-end-to-end-protection=0, init-value=0}, provided-interface=SR_CFG_TYPE_CAPTEUR_BOUCHON_CARB
      PP_SR_CFG_TYPE_CHAINE_TRACTION: nonqueued-sender-com-spec{data-element=CFG_TYPE_CHAINE_TRACTION, uses-end-to-end-protection=0, init-value=0}, provided-interface=SR_CFG_TYPE_CHAINE_TRACTION
      PP_SR_CFG_TYPE_FAP: nonqueued-sender-com-spec{data-element=CFG_TYPE_FAP, uses-end-to-end-protection=0, init-value=0}, provided-interface=SR_CFG_TYPE_FAP
      PP_SR_CFG_TYPE_FSE: nonqueued-sender-com-spec{data-element=CFG_TYPE_FSE, uses-end-to-end-protection=0, init-value=0}, provided-interface=SR_CFG_TYPE_FSE
      PP_SR_CFG_TYPE_FUNCTIONAL_ABSD: nonqueued-sender-com-spec{data-element=CFG_TYPE_FUNCTIONAL_ABSD, uses-end-to-end-protection=0, init-value=0}, provided-interface=SR_CFG_TYPE_FUNCTIONAL_ABSD
      PP_SR_CFG_TYPE_GPL_IHM: nonqueued-sender-com-spec{data-element=CFG_TYPE_GPL_IHM, uses-end-to-end-protection=0, init-value=0}, provided-interface=SR_CFG_TYPE_GPL_IHM
      PP_SR_CFG_TYPE_REGLAGE_SELECTIVITE: nonqueued-sender-com-spec{data-element=CFG_TYPE_REGLAGE_SELECTIVITE, uses-end-to-end-protection=0, init-value=0}, provided-interface=SR_CFG_TYPE_REGLAGE_SELECTIVITE
      PP_SR_CFG_TYPE_SC: nonqueued-sender-com-spec{data-element=CFG_TYPE_SC, uses-end-to-end-protection=0, init-value=0}, provided-interface=SR_CFG_TYPE_SC
      PP_SR_CFG_TYPE_SELECTIVITE: nonqueued-sender-com-spec{data-element=CFG_TYPE_SELECTIVITE, uses-end-to-end-protection=0, init-value=0}, provided-interface=SR_CFG_TYPE_SELECTIVITE
      PP_SR_CFG_TYPE_SELECTIVITE_OUV_AR: nonqueued-sender-com-spec{data-element=CFG_TYPE_SELECTIVITE_OUV_AR, uses-end-to-end-protection=0, init-value=0}, provided-interface=SR_CFG_TYPE_SELECTIVITE_OUV_AR
      PP_SR_T28_APPUI_LONG_TOUCHE_CONF: nonqueued-sender-com-spec{data-element=T28_APPUI_LONG_TOUCHE_CONF, uses-end-to-end-protection=0, init-value=0}, provided-interface=SR_T28_APPUI_LONG_TOUCHE_CONF
      PP_SR_T28_MAINTIEN_DONNEES_TOUCHE: nonqueued-sender-com-spec{data-element=T28_MAINTIEN_DONNEES_TOUCHE, uses-end-to-end-protection=0, init-value=0}, provided-interface=SR_T28_MAINTIEN_DONNEES_TOUCHE
      PP_SR_T7D1_BASE_TEMPS_ACQUISITION: nonqueued-sender-com-spec{data-element=T7D1_BASE_TEMPS_ACQUISITION, uses-end-to-end-protection=0, init-value=0}, provided-interface=SR_T7D1_BASE_TEMPS_ACQUISITION
      PP_SR_T7D1_DETECTION_DEFAUT_MVMT_VHL: nonqueued-sender-com-spec{data-element=T7D1_DETECTION_DEFAUT_MVMT_VHL, uses-end-to-end-protection=0, init-value=0}, provided-interface=SR_T7D1_DETECTION_DEFAUT_MVMT_VHL
      PP_SR_T7D1_DUREE_CONFIRM_ETAT_ELEC_BOUCHON: nonqueued-sender-com-spec{data-element=T7D1_DUREE_CONFIRM_ETAT_ELEC_BOUCHON, uses-end-to-end-protection=0, init-value=0}, provided-interface=SR_T7D1_DUREE_CONFIRM_ETAT_ELEC_BOUCHON
      PP_SR_T7D1_DUREE_CONFIRM_ETAT_OUBLI_BOUCHON: nonqueued-sender-com-spec{data-element=T7D1_DUREE_CONFIRM_ETAT_OUBLI_BOUCHON, uses-end-to-end-protection=0, init-value=0}, provided-interface=SR_T7D1_DUREE_CONFIRM_ETAT_OUBLI_BOUCHON
      PP_SR_T7D1_DUREE_FLAG_DETECTION_APPORT: nonqueued-sender-com-spec{data-element=T7D1_DUREE_FLAG_DETECTION_APPORT, uses-end-to-end-protection=0, init-value=0}, provided-interface=SR_T7D1_DUREE_FLAG_DETECTION_APPORT
      PP_SR_T7D1_TEMPO_FILTRAGE_ALIME: nonqueued-sender-com-spec{data-element=T7D1_TEMPO_FILTRAGE_ALIME, uses-end-to-end-protection=0, init-value=0}, provided-interface=SR_T7D1_TEMPO_FILTRAGE_ALIME
      PP_SR_T7D1_TEMPO_MAJ_NIV_TEMP: nonqueued-sender-com-spec{data-element=T7D1_TEMPO_MAJ_NIV_TEMP, uses-end-to-end-protection=0, init-value=0}, provided-interface=SR_T7D1_TEMPO_MAJ_NIV_TEMP
      PP_SR_T7D1_TEMPO_STAB_CARB: nonqueued-sender-com-spec{data-element=T7D1_TEMPO_STAB_CARB, uses-end-to-end-protection=0, init-value=0}, provided-interface=SR_T7D1_TEMPO_STAB_CARB
      PP_SR_T7D2_DUREE_MIN_PUSH_GPL: nonqueued-sender-com-spec{data-element=T7D2_DUREE_MIN_PUSH_GPL, uses-end-to-end-protection=0, init-value=0}, provided-interface=SR_T7D2_DUREE_MIN_PUSH_GPL
      PP_SR_T7D2_DeltaRelIhmMiniCarbZero: nonqueued-sender-com-spec{data-element=T7D2_DeltaRelIhmMiniCarbZero, uses-end-to-end-protection=0, init-value=0}, provided-interface=SR_T7D2_DeltaRelIhmMiniCarbZero
      PP_SR_T7D2_FAILURE_PUSH_GPL: nonqueued-sender-com-spec{data-element=T7D2_FAILURE_PUSH_GPL, uses-end-to-end-protection=0, init-value=0}, provided-interface=SR_T7D2_FAILURE_PUSH_GPL
      PP_SR_T7D2_FILTRE_LED_GPL: nonqueued-sender-com-spec{data-element=T7D2_FILTRE_LED_GPL, uses-end-to-end-protection=0, init-value=0}, provided-interface=SR_T7D2_FILTRE_LED_GPL
      PP_SR_T7D2_FILTRE_PUSH_GPL: nonqueued-sender-com-spec{data-element=T7D2_FILTRE_PUSH_GPL, uses-end-to-end-protection=0, init-value=0}, provided-interface=SR_T7D2_FILTRE_PUSH_GPL
      PP_SR_T7D2_TEMPO_FILTRAGE_IHM_MINICARB: nonqueued-sender-com-spec{data-element=T7D2_TEMPO_FILTRAGE_IHM_MINICARB, uses-end-to-end-protection=0, init-value=0}, provided-interface=SR_T7D2_TEMPO_FILTRAGE_IHM_MINICARB
      PP_SR_T7D2_TEMPO_LISSAGE: nonqueued-sender-com-spec{data-element=T7D2_TEMPO_LISSAGE, uses-end-to-end-protection=0, init-value=0}, provided-interface=SR_T7D2_TEMPO_LISSAGE
      PP_SR_T7D3_TEMPO_SEUIL_VITESSE: nonqueued-sender-com-spec{data-element=T7D3_TEMPO_SEUIL_VITESSE, uses-end-to-end-protection=0, init-value=0}, provided-interface=SR_T7D3_TEMPO_SEUIL_VITESSE
      PP_SR_TA7C_BOUCLAGE_CEINT_COND: nonqueued-sender-com-spec{data-element=TA7C_BOUCLAGE_CEINT_COND, uses-end-to-end-protection=0, init-value=0}, provided-interface=SR_TA7C_BOUCLAGE_CEINT_COND
      PP_SR_TA7C_CONFIRM_DEBOUCLAGE_CEINT: nonqueued-sender-com-spec{data-element=TA7C_CONFIRM_DEBOUCLAGE_CEINT, uses-end-to-end-protection=0, init-value=0}, provided-interface=SR_TA7C_CONFIRM_DEBOUCLAGE_CEINT
      PP_SR_TA7C_CONFIRM_OUVERTURE_PORTE: nonqueued-sender-com-spec{data-element=TA7C_CONFIRM_OUVERTURE_PORTE, uses-end-to-end-protection=0, init-value=0}, provided-interface=SR_TA7C_CONFIRM_OUVERTURE_PORTE
      PP_SR_TA7C_DUREE_FORCAGE_TEMOINS_ARR: nonqueued-sender-com-spec{data-element=TA7C_DUREE_FORCAGE_TEMOINS_ARR, uses-end-to-end-protection=0, init-value=0}, provided-interface=SR_TA7C_DUREE_FORCAGE_TEMOINS_ARR
      PP_SR_TA7C_FORCAGE_MAX_TNB: nonqueued-sender-com-spec{data-element=TA7C_FORCAGE_MAX_TNB, uses-end-to-end-protection=0, init-value=0}, provided-interface=SR_TA7C_FORCAGE_MAX_TNB
      PP_SR_TP7C_FILTRAGE_ABSENCE: nonqueued-sender-com-spec{data-element=TP7C_FILTRAGE_ABSENCE, uses-end-to-end-protection=0, init-value=0}, provided-interface=SR_TP7C_FILTRAGE_ABSENCE
      PP_SR_T_DUREE_SON_ANBC_NIV1: nonqueued-sender-com-spec{data-element=T_DUREE_SON_ANBC_NIV1, uses-end-to-end-protection=0, init-value=0}, provided-interface=SR_T_DUREE_SON_ANBC_NIV1
      PP_SR_T_DUREE_SON_ANBC_NIV1_PRIM: nonqueued-sender-com-spec{data-element=T_DUREE_SON_ANBC_NIV1_PRIM, uses-end-to-end-protection=0, init-value=0}, provided-interface=SR_T_DUREE_SON_ANBC_NIV1_PRIM
      PP_SR_T_DUREE_SON_ANBC_NIV2: nonqueued-sender-com-spec{data-element=T_DUREE_SON_ANBC_NIV2, uses-end-to-end-protection=0, init-value=0}, provided-interface=SR_T_DUREE_SON_ANBC_NIV2
      PP_SR_T_DUREE_SON_ANBC_NIV2_PRIM: nonqueued-sender-com-spec{data-element=T_DUREE_SON_ANBC_NIV2_PRIM, uses-end-to-end-protection=0, init-value=0}, provided-interface=SR_T_DUREE_SON_ANBC_NIV2_PRIM
      PP_SR_T_DUREE_SON_ANBC_NIV3: nonqueued-sender-com-spec{data-element=T_DUREE_SON_ANBC_NIV3, uses-end-to-end-protection=0, init-value=0}, provided-interface=SR_T_DUREE_SON_ANBC_NIV3
      PP_SR_T_DUREE_SON_ANBC_NIV3_PRIM: nonqueued-sender-com-spec{data-element=T_DUREE_SON_ANBC_NIV3_PRIM, uses-end-to-end-protection=0, init-value=0}, provided-interface=SR_T_DUREE_SON_ANBC_NIV3_PRIM
    require port RP_IndexTableInPartition: required-interface=SR_IndexTableInPartition
    require port RP_VIT_LVV: required-interface=PI_VIT_LVV
    behavior IB_ParamServer: handle-termination-and-restart=NO-SUPPORT
      data received event dre_IndexVIT_LVV: start-on-event=RUNF1_VIT_LVV, data=RP_IndexTableInPartition.IndexVIT_LVV
      timing event te_RUNF1_VIT_LVV: start-on-event=RUNF1_VIT_LVV, period=1.0
      runnable RUNF1_VIT_LVV
        data-receive-point-by-arguments:
          access drparg_IndexVIT_LVV: accessed-variable=RP_IndexTableInPartition.IndexVIT_LVV
        data-send-points:
          4 x access:
            dsp_SR_C28_VAL_CONS_VIT_LVV_MIN: accessed-variable=PP_SR_C28_VAL_CONS_VIT_LVV_MIN.C28_VAL_CONS_VIT_LVV_MIN
            dsp_SR_C28_VAL_CONS_VIT_LVV_MIN_MILES: accessed-variable=PP_SR_C28_VAL_CONS_VIT_LVV_MIN_MILES.C28_VAL_CONS_VIT_LVV_MIN_MILES
            dsp_SR_C28_VAL_CONS_VIT_RVV_MIN: accessed-variable=PP_SR_C28_VAL_CONS_VIT_RVV_MIN.C28_VAL_CONS_VIT_RVV_MIN
            dsp_SR_C28_VAL_CONS_VIT_RVV_MIN_MILES: accessed-variable=PP_SR_C28_VAL_CONS_VIT_RVV_MIN_MILES.C28_VAL_CONS_VIT_RVV_MIN_MILES
        parameter access pa_VIT_LVV: accessed-parameter=RP_VIT_LVV.VIT_LVV
package /RootP_PSWC_ParamDefinition
  impl type Array_VIT_LVV: category=ARRAY
    element Struct_VIT_LVV: array-size=2, array-size-handling=ALL-INDICES-SAME-ARRAY-SIZE, array-size-semantics=FIXED-SIZE, implementation-data-type=Struct_VIT_LVV
  parameter interface PI_VIT_LVV
    parameter data prototype VIT_LVV: sw-impl-policy=CONST, type=Array_VIT_LVV
  parameter sw component type PSWC_ParamDefinition
    provide port PP_VIT_LVV: parameter-provide-com-spec{init-value=[{short-label=P1, fields=[Val_SR_C28_VAL_CONS_VIT_LVV_MIN_MILES_0:0, Val_SR_C28_VAL_CONS_VIT_LVV_MIN_0:0, Val_SR_C28_VAL_CONS_VIT_RVV_MIN_0:0, Val_SR_C28_VAL_CONS_VIT_RVV_MIN_MILES_0:0]}, {short-label=P2, fields=[Val_SR_C28_VAL_CONS_VIT_LVV_MIN_MILES_1:1, Val_SR_C28_VAL_CONS_VIT_LVV_MIN_1:1, Val_SR_C28_VAL_CONS_VIT_RVV_MIN_1:1, Val_SR_C28_VAL_CONS_VIT_RVV_MIN_MILES_1:1]}], parameter=VIT_LVV}, provided-interface=PI_VIT_LVV
  impl type Struct_VIT_LVV: category=STRUCTURE
    4 x element, all with category=TYPE_REFERENCE:
      SR_C28_VAL_CONS_VIT_LVV_MIN_MILES: implementation-data-type=t_C28_VAL_CONS_VIT_LVV_MIN_MILES
      SR_C28_VAL_CONS_VIT_LVV_MIN: implementation-data-type=t_C28_VAL_CONS_VIT_LVV_MIN
      SR_C28_VAL_CONS_VIT_RVV_MIN: implementation-data-type=t_C28_VAL_CONS_VIT_RVV_MIN
      SR_C28_VAL_CONS_VIT_RVV_MIN_MILES: implementation-data-type=t_C28_VAL_CONS_VIT_RVV_MIN_MILES
package /RootP_Implementation
  swc implementation Implementation_ASWC_ParamServer: programming-language=C, sw-version=1.0.0, vendor-id=1, behavior=IB_ParamServer
    code-descriptors:
      code SRC: artifact-descriptors=autosar-engineering-object={short-label=EngObject, category=SWSRC}
    resource consumption Resources
